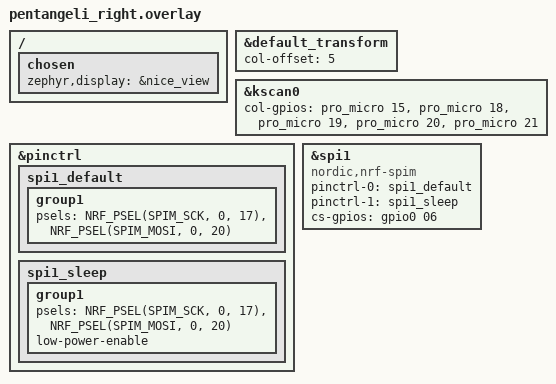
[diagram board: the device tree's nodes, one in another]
#include "pentangeli.dtsi"

&default_transform {
    col-offset = <5>;
};

&kscan0 {
    col-gpios
        = <&pro_micro 15 GPIO_ACTIVE_HIGH>
        , <&pro_micro 18 GPIO_ACTIVE_HIGH>
        , <&pro_micro 19 GPIO_ACTIVE_HIGH>
        , <&pro_micro 20 GPIO_ACTIVE_HIGH>
        , <&pro_micro 21 GPIO_ACTIVE_HIGH>
        ;
};

// Nice!view display
&pinctrl {
    spi1_default: spi1_default {
        group1 {
            psels = <NRF_PSEL(SPIM_SCK, 0, 17)>,
                <NRF_PSEL(SPIM_MOSI, 0, 20)>;
        };
    };
    spi1_sleep: spi1_sleep {
        group1 {
            psels = <NRF_PSEL(SPIM_SCK, 0, 17)>,
                <NRF_PSEL(SPIM_MOSI, 0, 20)>;
            low-power-enable;
        };
    };
};

nice_view_spi: &spi1 {
    compatible = "nordic,nrf-spim";
    pinctrl-0 = <&spi1_default>;
    pinctrl-1 = <&spi1_sleep>;
    pinctrl-names = "default", "sleep";
    cs-gpios = <&gpio0 06 GPIO_ACTIVE_HIGH>;
};

/ {
    chosen {
        zephyr,display = &nice_view;
    };
};
